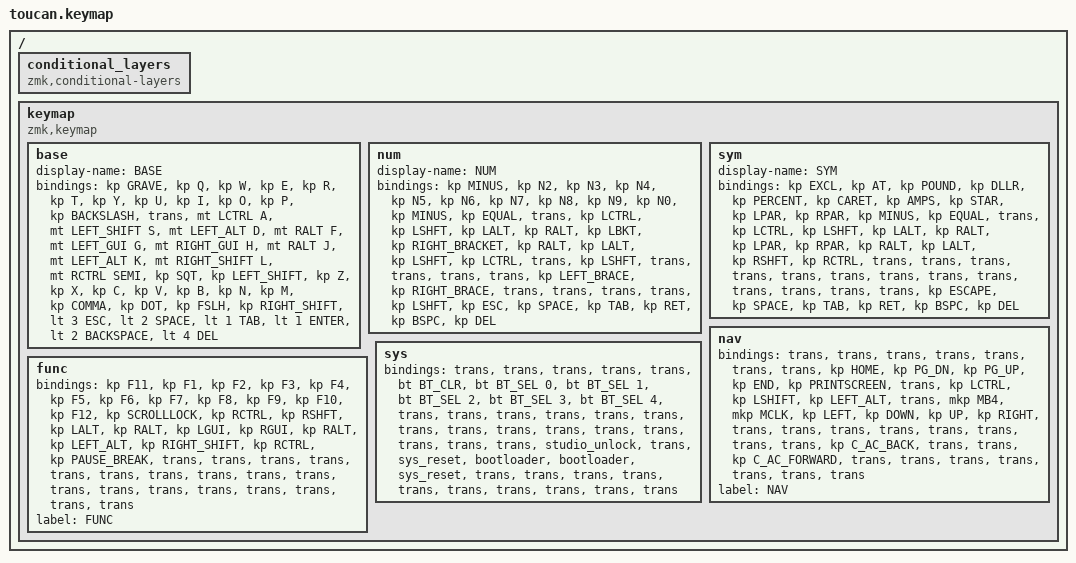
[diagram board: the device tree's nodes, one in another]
#include <behaviors.dtsi>
#include <dt-bindings/zmk/bt.h>
#include <dt-bindings/zmk/keys.h>
#include <dt-bindings/zmk/pointing.h>

#define BASE 0
#define NAV  1
#define SYM  2
#define ADJ  3

/ {
    conditional_layers { compatible = "zmk,conditional-layers"; };

    keymap {
        compatible = "zmk,keymap";

        base {
            display-name = "BASE";
            bindings = <
&kp GRAVE  &kp Q  &kp W  &kp E  &kp R  &kp T  &kp Y  &kp U  &kp I  &kp O  &kp P  &kp BACKSLASH  &trans  &mt LCTRL A  &mt LEFT_SHIFT S  &mt LEFT_ALT D  &mt RALT F  &mt LEFT_GUI G  &mt RIGHT_GUI H  &mt RALT J  &mt LEFT_ALT K  &mt RIGHT_SHIFT L  &mt RCTRL SEMI  &kp SQT  &kp LEFT_SHIFT  &kp Z  &kp X  &kp C  &kp V  &kp B  &kp N  &kp M  &kp COMMA  &kp DOT  &kp FSLH  &kp RIGHT_SHIFT  &lt 3 ESC  &lt 2 SPACE  &lt 1 TAB  &lt 1 ENTER  &lt 2 BACKSPACE  &lt 4 DEL
            >;
        };

        num {
            display-name = "NUM";
            bindings = <
&kp MINUS  &kp N2  &kp N3  &kp N4  &kp N5  &kp N6  &kp N7  &kp N8  &kp N9  &kp N0  &kp MINUS  &kp EQUAL  &trans  &kp LCTRL  &kp LSHFT  &kp LALT  &kp RALT  &kp LBKT  &kp RIGHT_BRACKET  &kp RALT  &kp LALT  &kp LSHFT  &kp LCTRL  &trans  &kp LSHFT  &trans  &trans  &trans  &trans  &kp LEFT_BRACE  &kp RIGHT_BRACE  &trans  &trans  &trans  &trans  &kp LSHFT  &kp ESC  &kp SPACE  &kp TAB  &kp RET  &kp BSPC  &kp DEL
            >;
        };

        sym {
            display-name = "SYM";
            bindings = <
&kp EXCL  &kp AT  &kp POUND  &kp DLLR  &kp PERCENT  &kp CARET  &kp AMPS  &kp STAR  &kp LPAR  &kp RPAR  &kp MINUS  &kp EQUAL  &trans  &kp LCTRL  &kp LSHFT  &kp LALT  &kp RALT  &kp LPAR  &kp RPAR  &kp RALT  &kp LALT  &kp RSHFT  &kp RCTRL  &trans  &trans  &trans  &trans  &trans  &trans  &trans  &trans  &trans  &trans  &trans  &trans  &trans  &kp ESCAPE  &kp SPACE  &kp TAB  &kp RET  &kp BSPC  &kp DEL
            >;
        };

        nav {
            bindings = <
&trans  &trans  &trans  &trans  &trans  &trans  &trans  &kp HOME  &kp PG_DN  &kp PG_UP  &kp END  &kp PRINTSCREEN  &trans  &kp LCTRL  &kp LSHIFT  &kp LEFT_ALT  &trans  &mkp MB4  &mkp MCLK  &kp LEFT  &kp DOWN  &kp UP  &kp RIGHT  &trans  &trans  &trans  &trans  &trans  &trans  &trans  &trans  &kp C_AC_BACK  &trans  &trans  &kp C_AC_FORWARD  &trans  &trans  &trans  &trans  &trans  &trans  &trans
            >;

            label = "NAV";
        };

        func {
            bindings = <
&kp F11  &kp F1  &kp F2  &kp F3  &kp F4  &kp F5  &kp F6  &kp F7  &kp F8  &kp F9  &kp F10  &kp F12  &kp SCROLLLOCK  &kp RCTRL  &kp RSHFT  &kp LALT  &kp RALT  &kp LGUI  &kp RGUI  &kp RALT  &kp LEFT_ALT  &kp RIGHT_SHIFT  &kp RCTRL  &kp PAUSE_BREAK  &trans  &trans  &trans  &trans  &trans  &trans  &trans  &trans  &trans  &trans  &trans  &trans  &trans  &trans  &trans  &trans  &trans  &trans
            >;

            label = "FUNC";
        };

        sys {
            bindings = <
&trans  &trans  &trans  &trans  &trans  &bt BT_CLR  &bt BT_SEL 0  &bt BT_SEL 1  &bt BT_SEL 2  &bt BT_SEL 3  &bt BT_SEL 4  &trans  &trans  &trans  &trans  &trans  &trans  &trans  &trans  &trans  &trans  &trans  &trans  &trans  &trans  &trans  &studio_unlock  &trans  &sys_reset  &bootloader  &bootloader  &sys_reset  &trans  &trans  &trans  &trans  &trans  &trans  &trans  &trans  &trans  &trans
            >;
        };
    };
};
